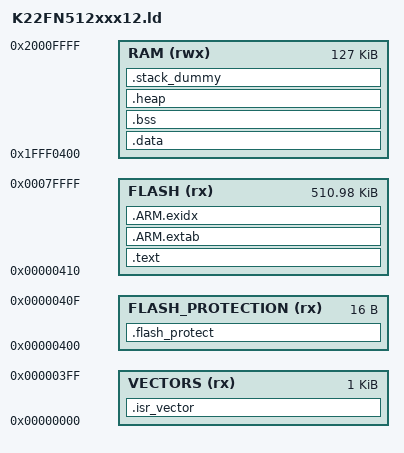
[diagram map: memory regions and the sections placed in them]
/*
 * K64F ARM GCC linker script file
 */

MEMORY
{
  VECTORS (rx)          : ORIGIN = 0x00000000, LENGTH = 0x00000400
  FLASH_PROTECTION (rx) : ORIGIN = 0x00000400, LENGTH = 0x00000010
  FLASH (rx)            : ORIGIN = 0x00000410, LENGTH = 0x000080000 - 0x00000410
  RAM (rwx)             : ORIGIN = 0x1FFF0400, LENGTH = 0x000020000 - 0x00000400
}

/* Linker script to place sections and symbol values. Should be used together
 * with other linker script that defines memory regions FLASH and RAM.
 * It references following symbols, which must be defined in code:
 * _reset_init : Entry of reset handler
 *
 * It defines following symbols, which code can use without definition:
 * __exidx_start
 * __exidx_end
 * __etext
 * __data_start__
 * __preinit_array_start
 * __preinit_array_end
 * __init_array_start
 * __init_array_end
 * __fini_array_start
 * __fini_array_end
 * __data_end__
 * __bss_start__
 * __bss_end__
 * __end__
 * end
 * __HeapLimit
 * __StackLimit
 * __StackTop
 * __stack
 */
ENTRY(Reset_Handler)

SECTIONS
{
    .isr_vector :
    {
        __vector_table = .;
        KEEP(*(.vector_table))
        *(.text.Reset_Handler)
        *(.text.System_Init)
         . = ALIGN(4);
    } > VECTORS

    .flash_protect :
    {
        KEEP(*(.kinetis_flash_config_field))
         . = ALIGN(4);
    } > FLASH_PROTECTION

    .text :
    {
        *(.text*)

        KEEP(*(.init))
        KEEP(*(.fini))

        /* .ctors */
        *crtbegin.o(.ctors)
        *crtbegin?.o(.ctors)
        *(EXCLUDE_FILE(*crtend?.o *crtend.o) .ctors)
        *(SORT(.ctors.*))
        *(.ctors)

        /* .dtors */
        *crtbegin.o(.dtors)
        *crtbegin?.o(.dtors)
        *(EXCLUDE_FILE(*crtend?.o *crtend.o) .dtors)
        *(SORT(.dtors.*))
        *(.dtors)

        *(.rodata*)

        KEEP(*(.eh_frame*))
    } > FLASH

    .ARM.extab :
    {
        *(.ARM.extab* .gnu.linkonce.armextab.*)
    } > FLASH

    __exidx_start = .;
    .ARM.exidx :
    {
        *(.ARM.exidx* .gnu.linkonce.armexidx.*)
    } > FLASH
    __exidx_end = .;

    __etext = .;

    .data : AT (__etext)
    {
        __data_start__ = .;
        *(vtable)
        *(.data*)

        . = ALIGN(4);
        /* preinit data */
        PROVIDE_HIDDEN (__preinit_array_start = .);
        KEEP(*(.preinit_array))
        PROVIDE_HIDDEN (__preinit_array_end = .);

        . = ALIGN(4);
        /* init data */
        PROVIDE_HIDDEN (__init_array_start = .);
        KEEP(*(SORT(.init_array.*)))
        KEEP(*(.init_array))
        PROVIDE_HIDDEN (__init_array_end = .);


        . = ALIGN(4);
        /* finit data */
        PROVIDE_HIDDEN (__fini_array_start = .);
        KEEP(*(SORT(.fini_array.*)))
        KEEP(*(.fini_array))
        PROVIDE_HIDDEN (__fini_array_end = .);

        . = ALIGN(4);
        /* All data end */
        __data_end__ = .;

    } > RAM

    .bss :
    {
        __bss_start__ = .;
        *(.bss*)
        *(COMMON)
        __bss_end__ = .;
    } > RAM

    .heap :
    {
        __end__ = .;
        end = __end__;
        *(.heap*)
        __HeapLimit = .;
    } > RAM

    /* .stack_dummy section doesn't contains any symbols. It is only
     * used for linker to calculate size of stack sections, and assign
     * values to stack symbols later */
    .stack_dummy :
    {
        *(.stack)
    } > RAM

    /* Set stack top to end of RAM, and stack limit move down by
     * size of stack_dummy section */
    __StackTop = ORIGIN(RAM) + LENGTH(RAM);
    __StackLimit = __StackTop - SIZEOF(.stack_dummy);
    PROVIDE(__stack = __StackTop);

    /* Check if data + heap + stack exceeds RAM limit */
    ASSERT(__StackLimit >= __HeapLimit, "region RAM overflowed with stack")
}

